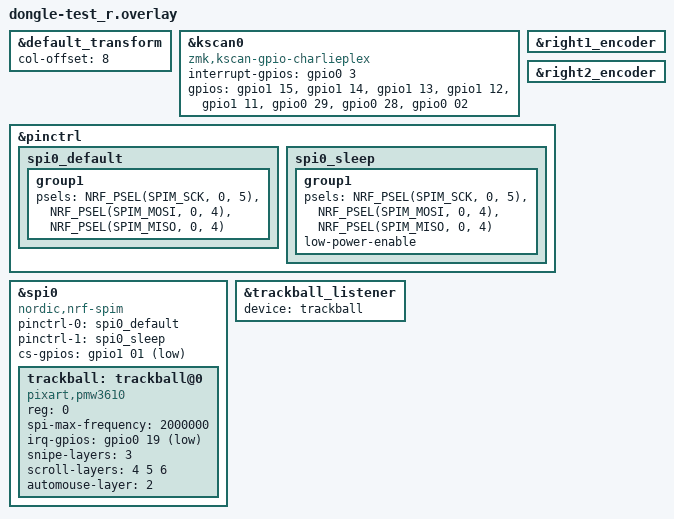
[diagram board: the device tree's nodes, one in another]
#include "dongle-test.dtsi"

&default_transform {
    col-offset = <8>;
};

    &kscan0 {
        compatible = "zmk,kscan-gpio-charlieplex";
        interrupt-gpios = <&gpio0 3 (GPIO_ACTIVE_HIGH | GPIO_PULL_DOWN)>; // IO2 = INTピン

        // Charlieplex用 5ピン定義 (IO0–IO4)
        gpios = 
        <&gpio1 15 GPIO_ACTIVE_HIGH>,  // IO0
        <&gpio1 14 GPIO_ACTIVE_HIGH>,  // IO1
        <&gpio1 13 GPIO_ACTIVE_HIGH>,  // IO2
        <&gpio1 12 GPIO_ACTIVE_HIGH>,  // IO3
        <&gpio1 11 GPIO_ACTIVE_HIGH>,  // IO4
        <&gpio0 29 GPIO_ACTIVE_HIGH>,  // IO5
        <&gpio0 28 GPIO_ACTIVE_HIGH>,  // IO6
        <&gpio0 02 GPIO_ACTIVE_HIGH>;  // IO7
    };

&right1_encoder {
   status = "okay";
};

&right2_encoder {
   status = "okay";
};

&pinctrl {
    spi0_default: spi0_default {
        group1 {
            psels = <NRF_PSEL(SPIM_SCK, 0, 5)>   // SCLK
                  , <NRF_PSEL(SPIM_MOSI, 0, 4)>  // SDIO
                  , <NRF_PSEL(SPIM_MISO, 0, 4)>  // SDIO
                  ;
        };
    };

    spi0_sleep: spi0_sleep {
        group1 {
            psels = <NRF_PSEL(SPIM_SCK, 0, 5)>   // SCLK
                  , <NRF_PSEL(SPIM_MOSI, 0, 4)>  // SDIO
                  , <NRF_PSEL(SPIM_MISO, 0, 4)>  // SDIO
                  ;
            low-power-enable;
        };
    };
};

&spi0 {
    status = "okay";
    compatible = "nordic,nrf-spim";
    pinctrl-0 = <&spi0_default>;
    pinctrl-1 = <&spi0_sleep>;
    pinctrl-names = "default", "sleep";
    cs-gpios = <&gpio1 01 GPIO_ACTIVE_LOW>; //NCS

    trackball: trackball@0 {
        status = "okay";
        compatible = "pixart,pmw3610";
        reg = <0>;
        spi-max-frequency = <2000000>;
        irq-gpios = <&gpio0 19 (GPIO_ACTIVE_LOW | GPIO_PULL_UP)>; //MOT
        
        snipe-layers = <3>;
        scroll-layers = <4 5 6>;
        automouse-layer = <2>;
    };
};

&trackball_listener {
    status = "okay";
    device = <&trackball>;
};


